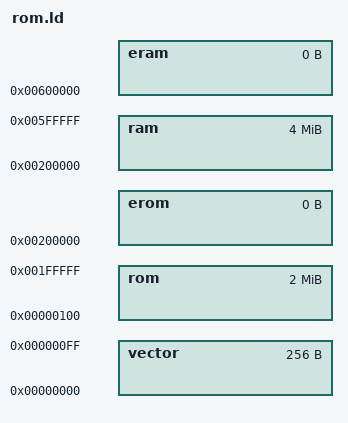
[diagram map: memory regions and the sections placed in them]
OUTPUT_ARCH(h8300h)
ENTRY("__start")

MEMORY 
	{
	vector : ORIGIN = 0x000000, LENGTH = 0x000100
	rom    : ORIGIN = 0x000100, LENGTH = 0x200000-0x000100
	erom   : ORIGIN = 0x200000, LENGTH = 0
	ram    : ORIGIN = 0x200000, LENGTH = 0x400000
	eram   : ORIGIN = 0x600000, LENGTH = 0
	}

